# R7KA8T2AD register map
Vendor: Renesas Electronics Corporation; Series: RA8; File version: 1.10.02
CPU: CM85 r0p2, little endian, MPU, FPU, VTOR, 4 interrupt priority bits, 96 interrupts
Registers are 32-bit, read-write, reset 0x0 unless marked. A register's access mark holds for its fields unless they carry their own. Offsets are from the block's base; [hi:lo] are bit positions; {n}, {i} and the like mark numbered series; 'fields as' and 'values as' point back to an identical list; <NAME> marks a mode.

## SYSC — System Control
Base 0x4001E000
0x0C SBYCR 8-bit reset 0x40 — Standby Control Register
  [6] OPE — Output Port Enable
    0=In Software Standby mode or Deep Software Standby mode, Set the address bus and other bus control signal to the high-impedance state; 1=In Software Standby mode or Deep Software Standby mode, Address bus and other bus control signal retain the output state
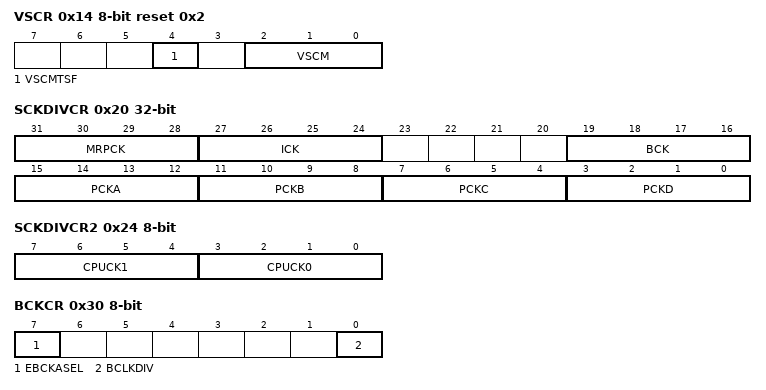
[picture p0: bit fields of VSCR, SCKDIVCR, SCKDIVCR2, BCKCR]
0x14 VSCR 8-bit reset 0x2 — Voltage Scaling Control Register
  [4] VSCMTSF ro — Voltage Scaling Control Mode Transition Status Flag
    0=Transition completed; 1=During transition
  [2:0] VSCM — Voltage Scaling Control Mode Bit
    1=VSCR_1; 2=VSCR_2 (default)
0x20 SCKDIVCR — System Clock Division Control Register
  [31:28] MRPCK — MRAM Clock (MRPCLK) Select
    0=x 1/1; 1=x 1/2; 2=x 1/4; 3=x 1/8; 4=x 1/16; 5=x 1/32; 6=x 1/64; 8=x 1/3; 9=x 1/6; 10=x 1/12; 11=x 1/24; other=Others (Setting prohibited.)
  [27:24] ICK — System Clock (ICLK) Select
    values as MRPCK
  [19:16] BCK — External Bus Clock (BCLK) Select
    0=x 1/1; 1=x 1/2; 2=x 1/4; 3=x 1/8; 4=x 1/16; 5=x 1/32; 6=x 1/64; 8=x 1/3; 9=x 1/6; 10=x 1/12; 11=x 1/24; other=Others (Settings prohibited)
  [15:12] PCKA — Peripheral Module Clock A (PCLKA) Select
    values as MRPCK
  [11:8] PCKB — Peripheral Module Clock B (PCLKB) Select
    values as MRPCK
  [7:4] PCKC — Peripheral Module Clock C (PCLKC) Select
    values as MRPCK
  [3:0] PCKD — Peripheral Module Clock D (PCLKD) Select
    values as MRPCK
0x24 SCKDIVCR2 8-bit — System Clock Division Control Register 2
  [7:4] CPUCK1 — CPU1 Clock (CPUCLK1) Select
    values as SCKDIVCR.MRPCK
  [3:0] CPUCK0 — CPU0 Clock (CPUCLK0) Select
    values as SCKDIVCR.MRPCK
0x26 SCKSCR 8-bit reset 0x1 — System Clock Source Control Register
  [2:0] CKSEL — Clock Source Select
    0=HOCO; 1=MOCO (Value after reset); 2=Setting prohibited; 3=Main clock oscillator (MOSC); 4=Sub-clock oscillator (SOSC); 5=PLL1 output clock P (PLL1P); 6=Setting prohibited; 7=Setting prohibited
0x2A PLLCR 8-bit reset 0x1 — PLL Control Register
  [0] PLLSTP — PLL1 Stop Control
    0=PLL1 is operating; 1=PLL1 is stopped
0x30 BCKCR 8-bit — External Bus Clock Control Register
  [7] EBCKASEL — External Bus Asynchronous Select
    0=Synchronous (BCLK); 1=Asynchronous (BCLKA)
  [0] BCLKDIV — BCLK Pin Output Select
    0=BCLK or BCLKA; 1=BCLK/2 or BCLKA/2
0x32 MOSCCR 8-bit reset 0x1 — Main Clock Oscillator Control Register
  [0] MOSTP — Main Clock Oscillator Stop
    0=Operate the main clock oscillator; 1=Stop the main clock oscillator
0x36 HOCOCR 8-bit (reset mask 0xFE) — High-Speed On-Chip Oscillator Control Register
  [0] HCSTP — HOCO Stop
    0=Operate the HOCO clock; 1=Stop the HOCO clock
0x37 HOCOCR2 8-bit (reset mask 0xF8) — High-Speed On-Chip Oscillator Control Register2
  [2:0] HCFRQ0 — HOCO Frequency Setting 0
    0=16 MHz; 1=18 MHz; 2=20 MHz; 4=32 MHz; 7=48 MHz
0x38 MOCOCR 8-bit — Middle-Speed On-Chip Oscillator Control Register
  [0] MCSTP — MOCO Stop
    0=MOCO clock is operating; 1=MOCO clock is stopped
0x39 FLLCR1 8-bit — FLL Control Register1
  [0] FLLEN — FLL Enable
    0=FLL function is disabled; 1=FLL function is enabled
0x3A FLLCR2 16-bit — FLL Control Register2
  [10:0] FLLCNTL — FLL Multiplication Control
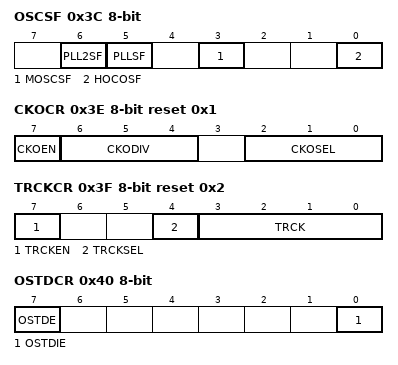
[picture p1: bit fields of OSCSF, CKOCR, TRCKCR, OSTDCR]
0x3C OSCSF 8-bit ro (reset mask 0xFE) — Oscillation Stabilization Flag Register
  [6] PLL2SF — PLL2 Clock Oscillation Stabilization Flag
    0=The PLL2 clock is stopped or is not yet stable; 1=The PLL2 clock is stable
  [5] PLLSF — PLL1 Clock Oscillation Stabilization Flag
    0=The PLL1 clock is stopped or is not yet stable; 1=The PLL1 clock is stable, so is available for use as the system clock source
  [3] MOSCSF — Main Clock Oscillation Stabilization Flag
    0=The main clock oscillator is stopped or is not yet stable; 1=The main clock oscillator is stable, so is available for use as the system clock source
  [0] HOCOSF — HOCO Clock Oscillation Stabilization Flag
    0=The HOCO clock is stopped or is not yet stable; 1=The HOCO clock is stable, so is available for use as the system clock source
0x3E CKOCR 8-bit reset 0x1 — Clock Out Control Register
  [7] CKOEN — Clock Out Enable
    0=Disable clock out; 1=Enable clock out
  [6:4] CKODIV — Clock Output Frequency Division Ratio
    0=x 1/1; 1=x 1/2; 2=x 1/4; 3=x 1/8; 4=x 1/16; 5=x 1/32; 6=x 1/64; 7=x 1/128
  [2:0] CKOSEL — Clock Out Source Select
    0=HOCO; 1=MOCO (Value after reset); 2=LOCO; 3=MOSC; 4=SOSC; other=Others (Setting prohibited)
0x3F TRCKCR 8-bit reset 0x2 — Trace Clock Control Register
  [7] TRCKEN — Trace Clock Operating Enable
    0=Stop; 1=Operation enable
  [4] TRCKSEL — Trace Clock Source Select
    0=System clock source (value after reset); 1=HOCO (oscillation in debug mode)
  [3:0] TRCK — Trace Clock Operating Frequency Select
    0=1/1; 1=1/2; 2=1/4 (value after reset); 3=1/8; 4=1/16; 5=1/32; 6=1/64; 7=1/128; 8=1/256; 9=1/3; 10=1/6; 11=1/12; other=Others (Setting prohibited)
0x40 OSTDCR 8-bit — Oscillation Stop Detection Control Register
  [7] OSTDE — Oscillation Stop Detection Function Enable
    0=Disable oscillation stop detection function; 1=Enable oscillation stop detection function
  [0] OSTDIE — Oscillation Stop Detection Interrupt Enable
    0=Disable oscillation stop detection interrupt (do not notify the POEG); 1=Enable oscillation stop detection interrupt (notify the POEG)
0x41 OSTDSR 8-bit — Oscillation Stop Detection Status Register
  [0] OSTDF — Oscillation Stop Detection Flag
    0=Main clock oscillation stop not detected; 1=Main clock oscillation stop detected
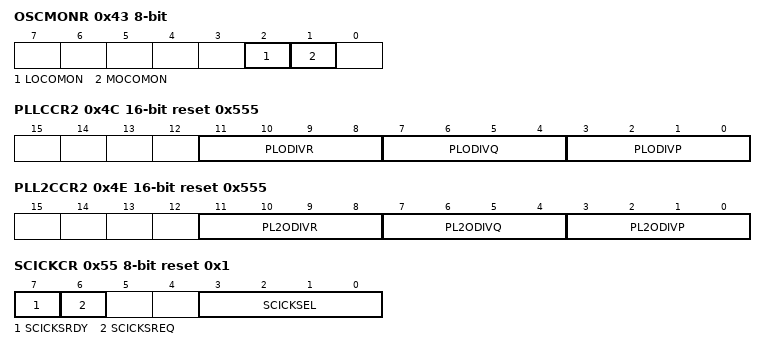
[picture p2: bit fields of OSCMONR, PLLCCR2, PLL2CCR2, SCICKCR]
0x43 OSCMONR 8-bit — Oscillator Monitor Register
  [2] LOCOMON ro — LOCO operation monitor
    0=LOCO is set to operate; 1=LOCO is set to stop
  [1] MOCOMON ro — MOCO operation monitor
    0=MOCO is set to operate; 1=MOCO is set to stop
0x4A PLL2CR 8-bit reset 0x1 — PLL2 Control Register
  [0] PLL2STP — PLL2 Stop Control
    0=PLL2 is operating; 1=PLL2 is stopped
0x4C PLLCCR2 16-bit reset 0x555 — PLL Clock Control Register 2
  [11:8] PLODIVR — PLL1 Output Frequency Division Ratio Select for output clock R
    {v}=× 1/{v+1} (v=1..4); 5=× 1/6 (Value after reset); 7=× 1/8; 8=× 1/9; 9=× 1/1.5; other=Others (Setting prohibited.)
  [7:4] PLODIVQ — PLL1 Output Frequency Division Ratio Select for output clock Q
    values as PLODIVR
  [3:0] PLODIVP — PLL1 Output Frequency Division Ratio Select for output clock P
    1=× 1/2; 2=× 1/3; 3=× 1/4; 5=× 1/6 (Value after reset); 7=× 1/8; 15=× 1/16; other=Others (Setting prohibited.)
0x4E PLL2CCR2 16-bit reset 0x555 — PLL2 Clock Control Register 2
  [11:8] PL2ODIVR — PLL2 Output Frequency Division Ratio Select for output clock R
    values as PLLCCR2.PLODIVR
  [7:4] PL2ODIVQ — PLL2 Output Frequency Division Ratio Select for output clock Q
    values as PLLCCR2.PLODIVR
  [3:0] PL2ODIVP — PLL2 Output Frequency Division Ratio Select for output clock P
    values as PLLCCR2.PLODIVP
0x52 EBCKOCR 8-bit — External Bus Clock Output Control Register
  [0] EBCKOEN — EBCLK Pin Output Control
    0=EBCLK pin output is disabled (fixed high); 1=EBCLK pin output is enabled
0x53 SDCKOCR 8-bit — SDRAM Clock Output Control Register
  [0] SDCKOEN — SDCLK Pin Output Control
    0=SDCLK pin output is disabled. (Fixed high); 1=SDCLK pin output is enabled
0x54 SCICKDIVCR 8-bit — SCI Clock Division Control Register
  [3:0] SCICKDIV — SCI clock (SCICLK) Division Select
    0=1/1 (Value after reset); 1=1/2; 2=1/4; 3=1/6; 4=1/8; 5=1/3; 6=1/5; 7=1/10; 8=1/16; 9=1/32; other=Others (Setting prohibited.)
0x55 SCICKCR 8-bit reset 0x1 — SCI Clock Control Register
  [7] SCICKSRDY ro — SCI Clock (SCICLK) Switching Ready state flag
    0=Impossible to switch; 1=Possible to switch
  [6] SCICKSREQ — SCI Clock (SCICLK) Switching Request
    0=No request; 1=Request switching
  [3:0] SCICKSEL — SCI Clock (SCICLK) Source Select
    0=HOCO; 1=MOCO (value after reset); 2=LOCO; 3=Main clock oscillator; 4=Sub-clock oscillator; 5=PLL1P; 6=PLL2P; 7=PLL1Q; 8=PLL1R; 9=PLL2Q; 10=PLL2R; other=Others (Setting prohibited)
0x56 SPICKDIVCR 8-bit — SPI Clock Division Control Register
  [3:0] SPICKDIV — SPI clock (SPICLK) Division Select
    values as SCICKDIVCR.SCICKDIV
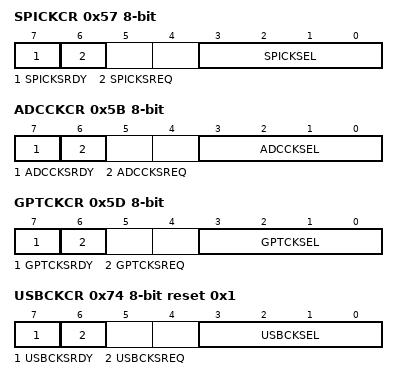
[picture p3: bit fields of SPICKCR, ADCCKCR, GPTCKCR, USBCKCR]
0x57 SPICKCR 8-bit — SPI Clock Control Register
  [7] SPICKSRDY ro — SPI clock (SPICLK) Switching Ready State Flag
    0=Impossible to switch; 1=Possible to switch
  [6] SPICKSREQ — SPI Clock (SPICLK) Switching Request
    0=No request; 1=Request switching
  [3:0] SPICKSEL — SPI Clock (SPICLK) Source Select
    values as SCICKCR.SCICKSEL
0x5A ADCCKDIVCR 8-bit — ADC Clock Division Control Register
  [3:0] ADCCKDIV — ADC Clock (ADCCLK) Division Select
    0=1/1 (value after reset); 1=1/2; 2=1/4; 3=1/6; 4=1/8; 7=1/10; 8=1/16; 9=1/32; other=Others (Setting prohibited)
0x5B ADCCKCR 8-bit — ADC Clock Control Register
  [7] ADCCKSRDY ro — ADC Clock (ADCCLK) Switching Ready State Flag
    0=Impossible to switch; 1=Possible to switch
  [6] ADCCKSREQ — ADC Clock (ADCCLK) Switching Request
    0=No request; 1=Request switching
  [3:0] ADCCKSEL — ADC Clock (ADCCLK) Source Select
    values as SCICKCR.SCICKSEL
0x5C GPTCKDIVCR 8-bit — GPT Clock Division Control Register
  [3:0] GPTCKDIV — GPT Clock (GPTCLK) Division Select
    0=1/1 (value after reset); 1=1/2; 2=1/4; 3=1/6; 4=1/8; 5=1/3; 6=1/5; 7=1/10; 8=1/16; 9=1/32; other=Others (Setting prohibited)
0x5D GPTCKCR 8-bit — GPT Clock Control Register
  [7] GPTCKSRDY — GPT Clock (GPTCLK) Switching Ready State Flag
    0=Impossible to switch; 1=Possible to switch
  [6] GPTCKSREQ — GPT Clock (GPTCLK) Switching Request
    0=No request; 1=Request switching
  [3:0] GPTCKSEL — GPT Clock (GPTCLK) Source Select
    0=HOCO; 1=MOCO (value after reset); 3=Main clock oscillator; 5=PLL1P; 6=PLL2P; 7=PLL1Q; 8=PLL1R; 9=PLL2Q; 10=PLL2R; other=Others (Setting prohibited.)
0x61 MOCOUTCR 8-bit — MOCO User Trimming Control Register
  [7:0] MOCOUTRM — MOCO User Trimming
0x62 HOCOUTCR 8-bit — HOCO User Trimming Control Register
  [7:0] HOCOUTRM — HOCO User Trimming
0x6C USBCKDIVCR 8-bit — USB Clock Division Control Register
  [3:0] USBCKDIV — USB Clock (USBCLK) Division Select
    0=1/1 (value after reset); 1=1/2; 2=1/4; 3=1/6; 4=1/8; 5=1/3; 6=1/5; 7=1/10; 8=1/16; 9=1/32; other=Others (Setting prohibited.)
0x6D OCTACKDIVCR 8-bit — Octal-SPI Clock Division Control Register
  [3:0] OCTACKDIV — Octal-SPI Clock (OCTACLK) Division Select
    values as SCICKDIVCR.SCICKDIV
0x6E CANFDCKDIVCR 8-bit — CANFD Core Clock Division Control Register
  [3:0] CANFDCKDIV — CANFD core clock (CANFDCLK) Division Select
    0=1/1 (Value after reset); 1=1/2; 2=1/4; 3=1/6; 4=1/8; 5=1/3; 6=1/5; 7=1/10; 8=1/16; 9=1/32; other=Others (Setting prohibited)
0x70 I3CCKDIVCR 8-bit — I3C Clock Division Control Register
  [3:0] I3CCKDIV — I3C clock (I3CCLK) Division Select
    values as SCICKDIVCR.SCICKDIV
0x74 USBCKCR 8-bit reset 0x1 — USB Clock Control Register
  [7] USBCKSRDY ro — USB Clock (USBCLK) Switching Ready state flag
    0=Impossible to Switch; 1=Possible to Switch
  [6] USBCKSREQ — USB Clock (USBCLK) Switching Request
    0=No request; 1=Request switching
  [3:0] USBCKSEL — USB Clock (USBCLK) Source Select
    0=HOCO; 1=MOCO (Value after reset); 3=Main clock oscillator; 5=PLL1P; 6=PLL2P; 7=PLL1Q; 8=PLL1R; 9=PLL2Q; 10=PLL2R; other=Others (Setting prohibited.)
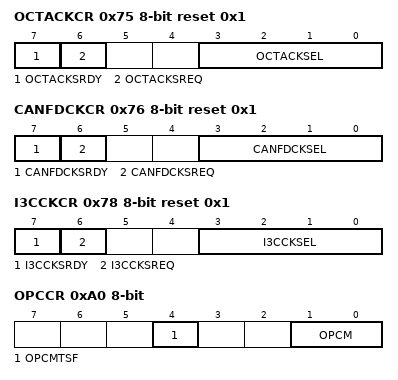
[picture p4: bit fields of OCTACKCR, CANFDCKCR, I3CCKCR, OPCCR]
0x75 OCTACKCR 8-bit reset 0x1 — Octal-SPI Clock Control Register
  [7] OCTACKSRDY ro — Octal-SPI Clock (OCTACLK) Switching Ready state flag
    0=Impossible to Switch; 1=Possible to Switch
  [6] OCTACKSREQ — Octal-SPI Clock (OCTACLK) Switching Request
    0=No request; 1=Request switching
  [3:0] OCTACKSEL — Octal-SPI Clock (OCTACLK) Source Select
    0=HOCO; 1=MOCO (Value after reset); 2=LOCO; 3=Main clock oscillator; 4=Sub-clock oscillator; 5=PLL1P; 6=PLL2P; 7=PLL1Q; 8=PLL1R; 9=PLL2Q; 10=PLL2R; other=Others (Setting prohibited.)
0x76 CANFDCKCR 8-bit reset 0x1 — CANFD Core Clock Control Register
  [7] CANFDCKSRDY ro — CANFD Core Clock (CANFDCLK) Switching Ready state flag
    0=Impossible to Switch; 1=Possible to Switch
  [6] CANFDCKSREQ — CANFD Core Clock (CANFDCLK) Switching Request
    0=No request; 1=Request switching
  [3:0] CANFDCKSEL — CANFD Core Clock (CANFDCLK) Source Select
    values as OCTACKCR.OCTACKSEL
0x78 I3CCKCR 8-bit reset 0x1 — I3C Clock Control Register
  [7] I3CCKSRDY ro — I3C Clock (I3CCLK) Switching Ready state flag
    0=Impossible to switch; 1=Possible to switch
  [6] I3CCKSREQ — I3C Clock (I3CCLK) Switching Request
    0=No request; 1=Request switching
  [3:0] I3CCKSEL — I3C Clock (I3CCLK) Source Select
    1=MOCO (value after reset); 5=PLL1P; 6=PLL2P; 7=PLL1Q; 8=PLL1R; 9=PLL2Q; 10=PLL2R
0x7C MOSCSCR 8-bit — Main Clock Oscillator Standby Control Register
  [0] MOSCSOKP — Main Clock Oscillator Standby Oscillation Keep select
    0=Disable; 1=Enable
0x7D HOCOSCR 8-bit — High-Speed On-Chip Oscillator Standby Control Register
  [0] HOCOSOKP — HOCO Standby Oscillation Keep select.
    0=Disable; 1=Enable
0x84 MOCOSCR 8-bit — Middle-Speed On-Chip Oscillator Standby Control Register
  [0] MOCOSOKP — MOCO Standby Oscillation Keep select
    0=Disable; 1=Enable
0xA0 OPCCR 8-bit — Operating Power Control Register
  [4] OPCMTSF ro — Operating Power Control Mode Transition Status Flag
    0=Transition completed; 1=During transition
  [1:0] OPCM — Operating Power Control Mode Select
    0=High-speed mode; 1=Prohibited; 2=Prohibited; 3=Prohibited
0xA2 MOSCWTCR 8-bit reset 0x5 — Main Clock Oscillator Wait Control Register
  [3:0] MSTS — Main Clock Oscillator Wait Time Setting
    0=Wait time = 3 cycles (11.4 us); 1=Wait time = 35 cycles (133.5 us); 2=Wait time = 67 cycles (255.6 us); 3=Wait time = 131 cycles (499.7 us); 4=Wait time = 259 cycles (988.0 us); 5=Wait time = 547 cycles (2086.6 us); 6=Wait time = 1059 cycles (4039.8 us); 7=Wait time = 2147 cycles (8190.2 us); 8=Wait time = 4291 cycles (16368.9 us); 9=Wait time = 8163 cycles (31139.4 us); other=Others (Setting prohibited)
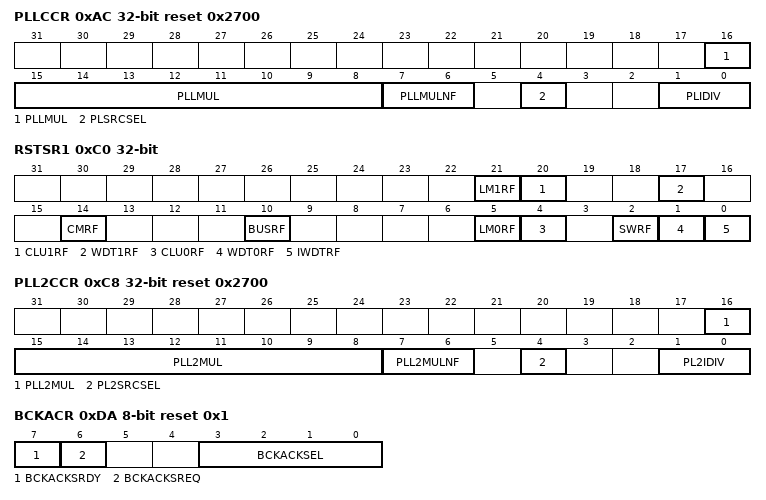
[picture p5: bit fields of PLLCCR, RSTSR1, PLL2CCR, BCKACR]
0xAC PLLCCR reset 0x2700 — PLL Clock Control Register
  [16:8] PLLMUL range 0x13..0x3B — PLL1 Frequency Multiplication Factor Select
  [7:6] PLLMULNF — PLL1 Frequency Multiplication Fractional Factor Select
    0=0.00 (Value after reset); 1=0.33 (1/3); 2=0.66 (2/3); 3=0.50 (1/2)
  [4] PLSRCSEL — PLL1 Clock Source Select
    0=Main clock oscillator; 1=HOCO
  [1:0] PLIDIV — PLL1 Input Frequency Division Ratio Select
    0=1/1; 1=1/2; 2=1/3; other=Others (Setting prohibited.)
0xC0 RSTSR1 (reset mask 0xFFCDBBC8) — Reset Status Register 1
  [21] LM1RF — Local memory 1 error Reset Detect Flag
    0=Local memory 1 error reset not detected; 1=Local memory 1 error reset detected
  [20] CLU1RF — CPU1 Lockup Reset Detect Flag
    0=CPU1 lockup reset not detected; 1=CPU1 lockup reset detected
  [17] WDT1RF — Watchdog Timer 1 Reset Detect Flag
    0=Watchdog timer 1 reset not detected; 1=Watchdog timer 1 reset detected
  [14] CMRF — Common Memory Error Reset Detect Flag
    0=Common memory error reset not detected; 1=Common memory error reset detected
  [10] BUSRF — Bus Error Reset Detect Flag
    0=Bus error reset not detected; 1=Bus error reset detected
  [5] LM0RF — Local memory 0 error Reset Detect Flag
    0=Local memory 0 error reset not detected; 1=Local memory 0 error reset detected
  [4] CLU0RF — CPU0 Lockup Reset Detect Flag
    0=CPU0 lockup reset not detected; 1=CPU0 lockup reset detected
  [2] SWRF — Software Reset Detect Flag
    0=Software reset not detected; 1=Software reset detected
  [1] WDT0RF — Watchdog Timer 0 Reset Detect Flag
    0=Watchdog timer 0 reset not detected; 1=Watchdog timer 0 reset detected
  [0] IWDTRF — Independent Watchdog Timer Reset Detect Flag
    0=Independent watchdog timer reset not detected; 1=Independent watchdog timer reset detected
0xC8 PLL2CCR reset 0x2700 — PLL2 Clock Control Register
  [16:8] PLL2MUL — PLL2 Frequency Multiplication Factor Select
  [7:6] PLL2MULNF — PLL2 Frequency Multiplication Fractional Factor Select
    values as PLLCCR.PLLMULNF
  [4] PL2SRCSEL — PLL2 Clock Source Select
    0=Main clock oscillator; 1=HOCO
  [1:0] PL2IDIV — PLL2 Input Frequency Division Ratio Select
    0=1/1 (Value after reset); 1=1/2; 2=1/3; other=Others (Setting prohibited.)
0xCC SYRACCR 8-bit ro — System Register Access Control Register
  [0] BUSY — Access Ready monitor
    0=Ready to read/write access; 1=Writing in progress
0xD4 BCKADIVCR 8-bit — Asynchronous External Bus Clock Division Control Register
  [3:0] BCKACKDIV — Asynchronous External Bus Clock (BCLKA) Division Select
    values as ADCCKDIVCR.ADCCKDIV
0xD5 ESWCKDIVCR 8-bit — EtherSW Clock Division Control Register
  [3:0] ESWCKDIV — EtherSW Clock (ESWCLK) Division Select
    values as ADCCKDIVCR.ADCCKDIV
0xD6 ESWPCKDIVCR 8-bit — EtherSW-PHY Clock Division Control Register
  [3:0] ESWPCKDIV — EtherSW-PHY Clock (ESWPHYCLK) Division Select
    values as ADCCKDIVCR.ADCCKDIV
0xD7 ESCCKDIVCR 8-bit — EtherCAT Clock Division Control Register
  [3:0] ESCCKDIV — EtherCAT Clock (ESCCLK) Division Select
    values as GPTCKDIVCR.GPTCKDIV
0xD8 ETHPCKDIVCR 8-bit — Ether-PHY Clock Division Control Register
  [3:0] ETHPCKDIV — Ether-PHY Clock (ETHPHYCLK) Division Select
    values as ADCCKDIVCR.ADCCKDIV
0xD9 DSMIFCKDIVCR 8-bit — DSMIF Clock Division Control Register
  [3:0] DSMIFCKDIV — DSMIF Clock (DSMIFCLK) Division Select
    values as GPTCKDIVCR.GPTCKDIV
0xDA BCKACR 8-bit reset 0x1 — Asynchronous External Bus Clock Control Register
  [7] BCKACKSRDY ro — Asynchronous External Bus Clock (BCLKA) Switching Ready State Flag
    0=Impossible to switch; 1=Possible to switch
  [6] BCKACKSREQ — Asynchronous External Bus Clock (BCLKA) Switching Request
    0=No request; 1=Request switching
  [3:0] BCKACKSEL — Asynchronous External Bus Clock (BCLKA)
    1=MOCO (value after reset); 5=PLL1P; 6=PLL2P; 7=PLL1Q; 8=PLL1R; 9=PLL2Q; 10=PLL2R; other=Others (Setting prohibited.)
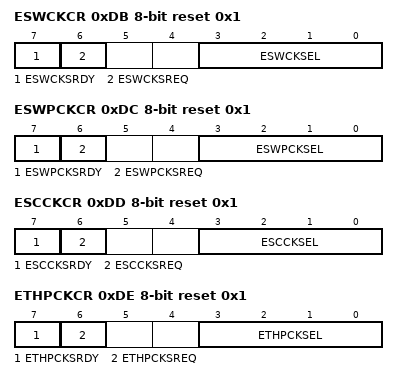
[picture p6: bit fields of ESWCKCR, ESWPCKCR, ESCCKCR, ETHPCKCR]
0xDB ESWCKCR 8-bit reset 0x1 — EtherSW Clock Control Register
  [7] ESWCKSRDY ro — EtherSW Clock (ESWCLK) Switching Ready State Flag
    0=Impossible to switch; 1=Possible to switch
  [6] ESWCKSREQ — EtherSW Clock (ESWCLK) Switching Request
    0=No request; 1=Request switching
  [3:0] ESWCKSEL — EtherSW Clock (ESWCLK) Source Select
    1=MOCO (value after reset); 5=PLL1P; 6=PLL2P; 7=PLL1Q; 8=PLL1R; 9=PLL2Q; 10=PLL2R; other=Others (Setting prohibited)
0xDC ESWPCKCR 8-bit reset 0x1 — EtherSW-PHY Clock Control Register
  [7] ESWPCKSRDY ro — EtherSW-PHY Clock (ESWPHYCLK) Switching Ready State Flag
    0=Impossible to switch; 1=Possible to switch
  [6] ESWPCKSREQ — EtherSW-PHY Clock (ESWPHYCLK) Switching Request
    0=No request; 1=Request switching
  [3:0] ESWPCKSEL — EtherSW-PHY Clock (ESWPHYCLK) Source Select
    values as ESWCKCR.ESWCKSEL
0xDD ESCCKCR 8-bit reset 0x1 — EtherCAT Clock Control Register
  [7] ESCCKSRDY ro — EtherCAT Clock (ESCCLK) Switching Ready State Flag
    0=Impossible to switch; 1=Possible to switch
  [6] ESCCKSREQ — EtherCAT Clock (ESCCLK) Switching Request
    0=No request; 1=Request switching
  [3:0] ESCCKSEL — EtherCAT Clock (ESCCLK) Source Select
    values as BCKACR.BCKACKSEL
0xDE ETHPCKCR 8-bit reset 0x1 — Ether-PHY Clock Control Register
  [7] ETHPCKSRDY ro — Ether-PHY Clock (ETHPHYCLK) Switching Ready State Flag
    0=Impossible to switch; 1=Possible to switch
  [6] ETHPCKSREQ — Ether-PHY Clock (ETHPHYCLK) Switching Request
    0=No request; 1=Request switching
  [3:0] ETHPCKSEL — Ether-PHY Clock (ETHPHYCLK) Source Select
    1=MOCO (value after reset); 3=Main clock oscillator; 5=PLL1P; 6=PLL2P; 7=PLL1Q; 8=PLL1R; 9=PLL2Q; 10=PLL2R; other=Others (Setting prohibited)
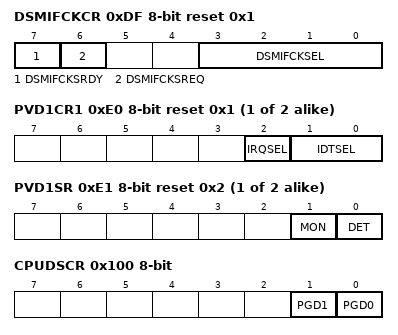
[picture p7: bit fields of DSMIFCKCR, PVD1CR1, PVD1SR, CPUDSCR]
0xDF DSMIFCKCR 8-bit reset 0x1 — DSMIF Clock Control Register
  [7] DSMIFCKSRDY ro — DSMIF Clock (DSMIFCLK) Switching Ready State Flag
    0=Impossible to switch; 1=Possible to switch
  [6] DSMIFCKSREQ — DSMIF Clock (DSMIFCLK) Switching Request
    0=No request; 1=Request switching
  [3:0] DSMIFCKSEL — DSMIF Clock (DSMIFCLK) Source Select
    values as BCKACR.BCKACKSEL
{0xDE+2i} PVD{i}CR1 (i=1..2) 8-bit reset 0x1 — Voltage Monitor {i} Circuit Control Register
  [2] IRQSEL — Voltage Monitor m Interrupt Type Select
    0=Non-maskable interrupt; 1=Maskable interrupt
  [1:0] IDTSEL — Voltage Monitor m Interrupt Generation Condition Select
{0xDF+2i} PVD{i}SR (i=1..2) 8-bit reset 0x2 — Voltage Monitor {i} Circuit Status Register
  [1] MON — Voltage Monitor 1 Signal Monitor Flag
  [0] DET — Voltage Monitor m Voltage Change Detection Flag
0x100 CPUDSCR 8-bit — CPU Deep Sleep Control Register
  [1] PGD1 — Power Gating Disable for CPU1
    0=Power Gating Enable during CPU1 Deep Sleep (default); 1=Power Gating Disable during CPU1 Deep Sleep
  [0] PGD0 — Power Gating Disable for CPU0
    0=Power Gating Enable during CPU0 Deep Sleep (default); 1=Power Gating Disable during CPU0 Deep Sleep
0x104 PGSCR 8-bit reset 0x1 — Power Gating Shift Control Register
  [0] PGS — Power gating shift timing
    0=Power gating control for each domain is started partial at the same time; 1=Power gating control for each domain is started serially
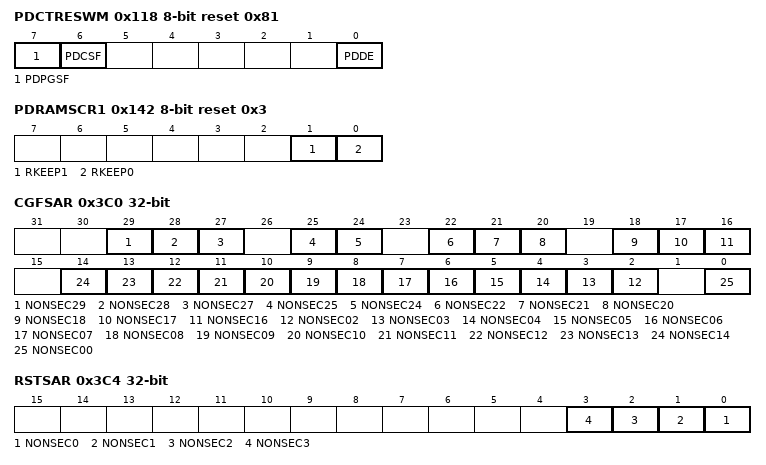
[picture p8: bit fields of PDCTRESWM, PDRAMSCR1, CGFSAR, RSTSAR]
0x118 PDCTRESWM 8-bit reset 0x81 — ESWM Power Domain Control Register
  [7] PDPGSF ro — Power gating status flag
    0=Target domain is power on (not gating); 1=Target domain is power off (during Gating)
  [6] PDCSF ro — Power control status flag
    0=Power gating control is not executed (idle); 1=Power gating control is in progress
  [0] PDDE — Power control enable
    0=Power on the target domain; 1=Power off the target domain
0x140 PDRAMSCR0 16-bit reset 0x7FFF — SRAM Power Domain Standby Control Register 0
  [12:0] RKEEP — RAM Retention
    0=When entering the Software Standby mode, the contents of the target RAM are not kept; 1=When entering the Software Standby mode, the contents of the target RAM are kept
0x142 PDRAMSCR1 8-bit reset 0x3 — SRAM Power Domain Standby Control Register 1
  [1] RKEEP1 — RAM Retention
    values as PDRAMSCR0.RKEEP
  [0] RKEEP0 — RAM Retention
    0=When entering the CPU0 Deep Sleep and Software Standby mode, the contents of the target RAM are not kept; 1=When entering the CPU0 Deep Sleep and Software Standby mode, the contents of the target RAM are kept
{0x210+2i} PSSTCR{i} (i=2..5) 16-bit — Power Switch Control Start Time Control Register {i}
  [12:0] PSST — Power switch control start time
0x3B0 VBRSABAR 16-bit reset 0xFFE0 — VBATT Backup Register Security Attribute Boundary Address Register
  [15:0] SABA — Boundary address between secure and non-secure
0x3B4 VBRPABARS 16-bit — VBATT Backup Register Privilege Attribute Boundary Address Register for Secure Region
  [15:0] PABAS — Privilege Attribute Boundary Address for Secure Region
0x3C0 CGFSAR — Clock Generation Function Security Attribute Register
  [all] fields
    0=Secure; 1=Non Secure
  [29] NONSEC29 — Non Secure Attribute bit 29
  [28] NONSEC28 — Non Secure Attribute bit 28
  [27] NONSEC27 — Non Secure Attribute bit 27
  [25] NONSEC25 — Non Secure Attribute bit 25
  [24] NONSEC24 — Non Secure Attribute bit 24
  [22] NONSEC22 — Non Secure Attribute bit 22
  [21] NONSEC21 — Non Secure Attribute bit 21
  [20] NONSEC20 — Non Secure Attribute bit 20
  [18] NONSEC18 — Non Secure Attribute bit 18
  [17] NONSEC17 — Non Secure Attribute bit 17
  [16] NONSEC16 — Non Secure Attribute bit 16
  [n] NONSEC{n:02} (n=2..14) — Non Secure Attribute bit {n:02}
  [0] NONSEC00 — Non Secure Attribute bit 00
0x3C4 RSTSAR — Reset Security Attribution Register
  [all] fields
    0=Secure; 1=Non-secure
  [n] NONSEC{n} (n=0..3) — Non-secure Attribute bit {n}
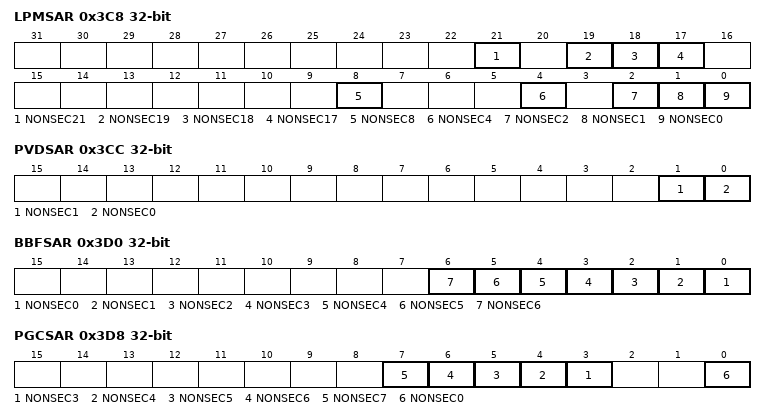
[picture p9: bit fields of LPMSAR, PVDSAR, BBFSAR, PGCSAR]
0x3C8 LPMSAR — Low Power Mode Security Attribution Register
  [all] fields
    0=Secure; 1=Non-secure
  [21] NONSEC21 — Non-secure Attribute bit 21
  [19] NONSEC19 — Non-secure Attribute bit 19
  [18] NONSEC18 — Non-secure Attribute bit 18
  [17] NONSEC17 — Non-secure Attribute bit 17
  [8] NONSEC8 — Non-secure Attribute bit 8
  [4] NONSEC4 — Non-secure Attribute bit 4
  [2] NONSEC2 — Non-secure Attribute bit 2
  [1] NONSEC1 — Non-secure Attribute bit 1
  [0] NONSEC0 — Non-secure Attribute bit 0
0x3CC PVDSAR — Programable Voltage Detection Security Attribution Register
  [1] NONSEC1 — Non Secure Attribute bit 1
    0=Secure; 1=Non Secure
  [0] NONSEC0 — Non Secure Attribute bit 0
    0=Secure; 1=Non Secure
0x3D0 BBFSAR — Battery Backup Function Security Attribute Register
  [all] fields
    0=Secure; 1=Non Secure
  [n] NONSEC{n} (n=0..6) — Non Secure Attribute bit {n}
0x3D8 PGCSAR — Power Gating Control Security Attribution Register
  [all] fields
    0=Secure; 1=Non-secure
  [n] NONSEC{n} (n=3..7) — Non-secure Attribute bit {n}
  [0] NONSEC0 — Non-secure Attribute bit 0
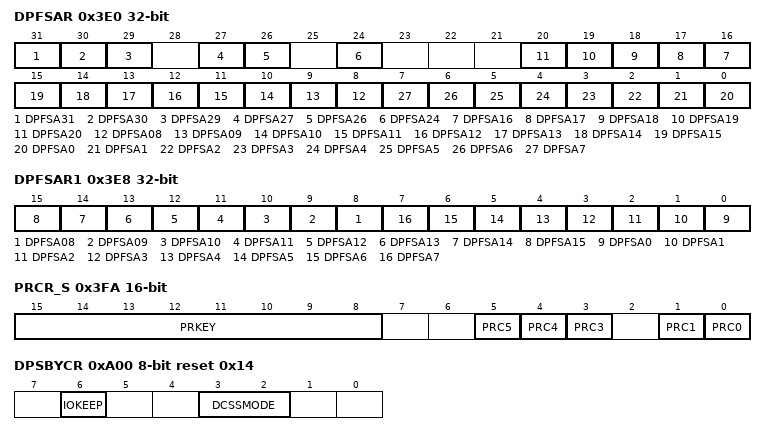
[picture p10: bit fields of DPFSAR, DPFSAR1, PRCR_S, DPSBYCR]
0x3E0 DPFSAR — Deep Software Standby Interrupt Factor Security Attribution Register
  [all] fields
    0=Secure; 1=Non-secure
  [31] DPFSA31 — Deep Software Standby Interrupt Factor Security Attribute bit 31
  [30] DPFSA30 — Deep Software Standby Interrupt Factor Security Attribute bit 30
  [29] DPFSA29 — Deep Software Standby Interrupt Factor Security Attribute bit 29
  [27] DPFSA27 — Deep Software Standby Interrupt Factor Security Attribute bit 27
  [26] DPFSA26 — Deep Software Standby Interrupt Factor Security Attribute bit 26
  [24] DPFSA24 — Deep Software Standby Interrupt Factor Security Attribute bit 24
  [n] DPFSA{n} (n=16..20) — Deep Software Standby Interrupt Factor Security Attribute bit {n}
  [n] DPFSA{n:02} (n=8..15) — Deep Software Standby Interrupt Factor Security Attribute bit n (n = 8 to 15)
  [n] DPFSA{n} (n=0..7) — Deep Software Standby Interrupt Factor Security Attribute bit n (n = 0 to 7)
0x3E4 RSCSAR — RAM Standby Control Security Attribution Register
  [17:0] RSCSA — RAM Standby Control Security Attribute bit n (n = 0 to 17)
    0=Secure; 1=Non-secure
0x3E8 DPFSAR1 — Deep Software Standby Interrupt Factor Security Attribution Register 1
  [all] fields
    0=Secure; 1=Non-secure
  [n] DPFSA{n:02} (n=8..15) — Deep Software Standby Interrupt Factor Security Attribute bit n (n = 8 to 15)
  [n] DPFSA{n} (n=0..7) — Deep Software Standby Interrupt Factor Security Attribute bit n (n = 0 to 7)
0x3FA PRCR_S 16-bit — Protect Register for Secure
  [15:8] PRKEY wo — PRC Key Code
  [5] PRC5
    0=Write disabled; 1=Write enabled
  [4] PRC4
    0=Write disabled; 1=Write enabled
  [3] PRC3 — Enable writing to the registers related to the PVD
    0=Write disabled; 1=Write enabled
  [1] PRC1 — Enable writing to the registers related to the low power modes, and the battery backup function
    0=Write disabled; 1=Write enabled
  [0] PRC0 — Enable writing to the registers related to the clock generation circuit
    0=Write disabled; 1=Write enabled
0x400 LOCOCR 8-bit — Low-Speed On-Chip Oscillator Control Register
  [0] LCSTP — LOCO Stop
    0=Operate the LOCO clock; 1=Stop the LOCO clock
0x402 LOCOUTCR 8-bit — LOCO User Trimming Control Register
  [7:0] LOCOUTRM — LOCO User Trimming
0xA00 DPSBYCR 8-bit reset 0x14 — Deep Software Standby Control Register
  [6] IOKEEP — I/O Port Retention
    0=When the Deep Software Standby mode is canceled, the I/O ports and D/A output are in the reset state; 1=When the Deep Software Standby mode is canceled, the I/O ports and D/A output are in the same state as in the Deep Software Standby mode
  [3:2] DCSSMODE — DCDC soft start mode
    0=Setting prohibited; 1=128 µs; 2=256 µs; 3=512 µs
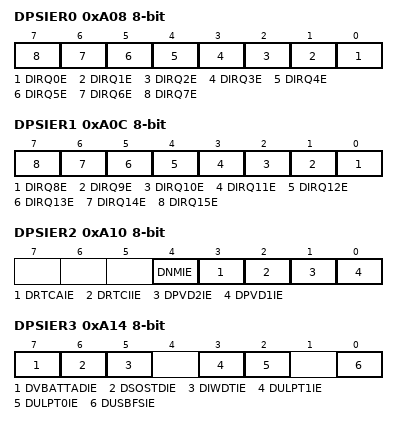
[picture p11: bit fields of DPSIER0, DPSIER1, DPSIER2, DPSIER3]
0xA08 DPSIER0 8-bit — Deep Software Standby Interrupt Enable Register 0
  [all] fields
    0=Cancelling Deep Software Standby mode is disabled; 1=Cancelling Deep Software Standby mode is enabled
  [n] DIRQ{n}E (n=0..7) — IRQ{n}-DS Pin Enable
0xA0C DPSIER1 8-bit — Deep Software Standby Interrupt Enable Register 1
  [all] fields
    0=Canceling Deep Software Standby mode is disabled; 1=Canceling Deep Software Standby mode is enabled
  [n-8] DIRQ{n}E (n=8..15) — IRQ{n}-DS Pin Enable
0xA10 DPSIER2 8-bit — Deep Software Standby Interrupt Enable Register 2
  [all] fields
    values as the fields of DPSIER1
  [4] DNMIE — NMI Pin Deep Software Standby Cancel Signal Enable
  [3] DRTCAIE — RTC Alarm interrupt Deep Software Standby Cancel Signal Enable
  [2] DRTCIIE — RTC Interval interrupt Deep Software Standby Cancel Signal Enable
  [1] DPVD2IE — PVD2 Deep Software Standby Cancel Signal Enable
  [0] DPVD1IE — PVD1 Deep Software Standby Cancel Signal Enable
0xA14 DPSIER3 8-bit — Deep Software Standby Interrupt Enable Register 3
  [all] fields
    values as the fields of DPSIER1
  [7] DVBATTADIE — VBATT Tamper Detection Deep Software Standby Cancel Signal Enable
  [6] DSOSTDIE — Sub-clock Oscillation stop detection Deep Software Standby Cancel Signal Enable
  [5] DIWDTIE — IWDT Overflow Deep Software Standby Cancel Signal Enable
  [3] DULPT1IE — ULPT1 Overflow Deep Software Standby Cancel Signal Enable
  [2] DULPT0IE — ULPT0 Overflow Deep Software Standby Cancel Signal Enable
  [0] DUSBFSIE — USBFS Suspend/Resume Deep Software Standby Cancel Signal Enable
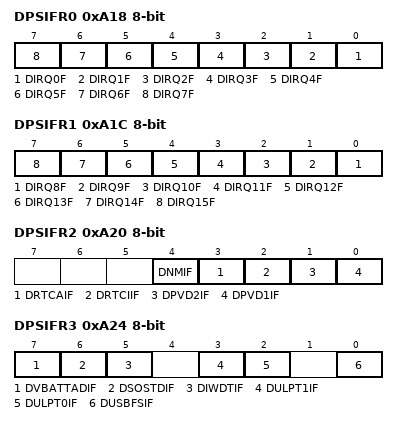
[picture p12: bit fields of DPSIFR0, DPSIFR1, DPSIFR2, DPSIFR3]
0xA18 DPSIFR0 8-bit — Deep Software Standby Interrupt Flag Register 0
  [all] fields
    0=The cancel request is not generated; 1=The cancel request is generated
  [n] DIRQ{n}F (n=0..7) — IRQ{n}-DS Pin Deep Software Standby Cancel Flag
0xA1C DPSIFR1 8-bit — Deep Software Standby Interrupt Flag Register 1
  [all] fields
    values as the fields of DPSIFR0
  [n-8] DIRQ{n}F (n=8..15) — IRQ{n}-DS Pin Deep Software Standby Cancel Flag
0xA20 DPSIFR2 8-bit — Deep Software Standby Interrupt Flag Register 2
  [all] fields
    values as the fields of DPSIFR0
  [4] DNMIF — NMI Pin Deep Software Standby Cancel Flag
  [3] DRTCAIF — RTC Alarm Interrupt Deep Software Standby Cancel Flag
  [2] DRTCIIF — RTC Interval Interrupt Deep Software Standby Cancel Flag
  [1] DPVD2IF — PVD2 Deep Software Standby Cancel Flag
  [0] DPVD1IF — PVD1 Deep Software Standby Cancel Flag
0xA24 DPSIFR3 8-bit — Deep Software Standby Interrupt Flag Register 3
  [all] fields
    values as the fields of DPSIFR0
  [7] DVBATTADIF — VBATT Tamper Detection Deep Software Standby Cancel Flag
  [6] DSOSTDIF — Sub-clock Oscillation stop detection Deep Software Standby Cancel Flag
  [5] DIWDTIF — IWDT Overflow Deep Software Standby Cancel Flag
  [3] DULPT1IF — ULPT1 Overflow Deep Software Standby Cancel Flag
  [2] DULPT0IF — ULPT0 Overflow Deep Software Standby Cancel Flag
  [0] DUSBFSIF — USBFS Suspend/Resume Deep Software Standby Cancel Flag
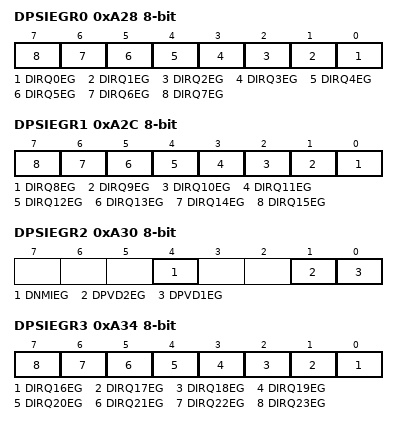
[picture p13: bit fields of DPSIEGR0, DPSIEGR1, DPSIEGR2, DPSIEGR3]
0xA28 DPSIEGR0 8-bit — Deep Software Standby Interrupt Edge Register 0
  [all] fields
    0=A cancel request is generated at a falling edge; 1=A cancel request is generated at a rising edge
  [n] DIRQ{n}EG (n=0..7) — IRQ{n}-DS Pin Edge Select
0xA2C DPSIEGR1 8-bit — Deep Software Standby Interrupt Edge Register 1
  [all] fields
    values as the fields of DPSIEGR0
  [n-8] DIRQ{n}EG (n=8..15) — IRQ{n}-DS Pin Edge Select
0xA30 DPSIEGR2 8-bit — Deep Software Standby Interrupt Edge Register 2
  [4] DNMIEG — NMI Pin Edge Select
    values as the fields of DPSIEGR0
  [1] DPVD2EG — PVD2 Edge Select
    0=A cancel request is generated when VCC < Vdet2 (fall) is detected; 1=A cancel request is generated when VCC ≥ Vdet2 (rise) is detected
  [0] DPVD1EG — PVD1 Edge Select
    0=A cancel request is generated when VCC < Vdet1 (fall) is detected; 1=A cancel request is generated when VCC ≥ Vdet1 (rise) is detected
0xA34 DPSIEGR3 8-bit — Deep Software Standby Interrupt Edge Register 3
  [all] fields
    values as the fields of DPSIEGR0
  [n-16] DIRQ{n}EG (n=16..23) — IRQ{n}-DS Pin Edge Select
0xA38 SYOCDCR 8-bit reset 0x80 — System Control OCD Control Register
  [7] DBGEN — Debugger Enable bit
    0=Disable on-chip debugger function; 1=Enable on-chip debugger function
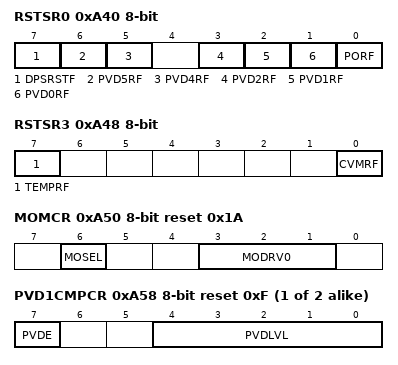
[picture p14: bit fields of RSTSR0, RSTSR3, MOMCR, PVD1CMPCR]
0xA40 RSTSR0 8-bit (reset mask 0x10) — Reset Status Register 0
  [7] DPSRSTF — Deep Software Standby Reset Flag
    0=Deep Software Standby Mode cancellation not requested by an interrupt or a reset; 1=Deep Software Standby Mode cancellation requested by an interrupt or a reset
  [6] PVD5RF — Voltage Monitor 5 Reset Detect Flag
    0=Voltage monitor 5 reset not detected; 1=Voltage monitor 5 reset detected
  [5] PVD4RF — Voltage Monitor 4 Reset Detect Flag
    0=Voltage monitor 4 reset not detected; 1=Voltage monitor 4 reset detected
  [3] PVD2RF — Voltage Monitor 2 Reset Detect Flag
    0=Voltage monitor 2 reset not detected; 1=Voltage monitor 2 reset detected
  [2] PVD1RF — Voltage Monitor 1 Reset Detect Flag
    0=Voltage monitor 1 reset not detected; 1=Voltage monitor 1 reset detected
  [1] PVD0RF — Voltage Monitor 0 Reset Detect Flag
    0=Voltage monitor 0 reset not detected; 1=Voltage monitor 0 reset detected
  [0] PORF — Power-On Reset Detect Flag
    0=Power-on reset not detected; 1=Power-on reset detected
0xA44 RSTSR2 8-bit (reset mask 0xFE) — Reset Status Register 2
  [0] CWSF — Cold/Warm Start Determination Flag
    0=Cold start; 1=Warm start
0xA48 RSTSR3 8-bit (reset mask 0x7E) — Reset Status Register 3
  [7] TEMPRF — Temperature Monitor Reset Detect Flag
    0=Temperature monitor reset not detected; 1=Temperature monitor reset detected
  [0] CVMRF — Core Voltage Monitor Reset Detect Flag
    0=Core voltage monitor reset not detected; 1=Core voltage monitor reset detected
0xA50 MOMCR 8-bit reset 0x1A — Main Clock Oscillator Mode Oscillation Control Register
  [6] MOSEL — Main Clock Oscillator Switching
    0=Resonator; 1=External clock input
  [3:1] MODRV0 — Main Clock Oscillator Drive Capability 0 Switching
    0=8 MHz; 3=8MHz to 24MHz; 5=8MHz to 48MHz; other=Others (Setting prohibited)
0xA54 FWEPROR 8-bit reset 0x2 — Flash P/E Protect Register
  [1:0] FLWE — Flash Programming and Erasure
    0=Prohibits Program, Block Erase, Multi Block Erase, Blank Check, and Configuration set command processing; 1=Permits Program, Block Erase, Multi Block Erase, Blank Check, and Configuration set command processing; 2=Prohibits Program, Block Erase, Multi Block Erase, Blank Check, and Configuration set command processing; 3=Prohibits Program, Block Erase, Multi Block Erase, Blank Check, and Configuration set command processing
{0xA54+4i} PVD{i}CMPCR (i=1..2) 8-bit reset 0xF — Voltage Monitor {i} Comparator Control Register
  [7] PVDE — Voltage Detection m Enable
    0=Voltage detection m circuit disabled; 1=Voltage detection m circuit enabled
  [4:0] PVDLVL — Detection Voltage m Level Select
    3=3.86 V (Vdetm_3); 4=3.14 V (Vdetm_4); 5=3.10 V (Vdetm_5); 6=3.08 V (Vdetm_6); 7=2.85 V (Vdetm_7); 8=2.83 V (Vdetm_8); 9=2.80 V (Vdetm_9); 10=2.62V (Vdetm_10); 11=2.33V (Vdetm_11); 12=1.90V (Vdetm_12); 13=1.86V (Vdetm_13); 14=1.74V (Vdetm_14); 15=1.71V (Vdetm_15); other=Others (Setting prohibited)
{0xA54+4i} PVD{i}CMPCR (i=4..5) 8-bit reset 0xF — Voltage Monitor {i} Comparator Control Register
  [7] PVDE — Voltage Detection n Enable
    0=Voltage detection n circuit disabled; 1=Voltage detection n circuit enabled
  [4:0] PVDLVL — Detection Voltage n Level Select
{0xA6C+4i} PVD{i}CR0 (i=1..2) 8-bit reset 0x82 — Voltage Monitor {i} Circuit Control Register 0
  [7] RN — Voltage Monitor m Reset Negate Select
  [6] RI — Voltage Monitor m Circuit Mode Select
  [5:4] FSAMP — Sampling Clock Select
    0=1/2 LOCO frequency; 1=1/4 LOCO frequency; 2=1/8 LOCO frequency; 3=1/16 LOCO frequency
  [2] CMPE — Voltage Monitor m Circuit Comparison Result Output Enable
    0=Voltage monitor m circuit comparison result output disabled; 1=Voltage monitor m circuit comparison result output enabled
  [1] DFDIS — Voltage monitor m Digital Filter Disabled Mode Select
    0=Enable the digital filter; 1=Disable the digital filter
  [0] RIE — Voltage Monitor m Interrupt/Reset Enable
    0=Disable; 1=Enable
{0xA6C+4i} PVD{i}CR0 (i=4..5) 8-bit reset 0x42 — Voltage Monitor {i} Circuit Control Register 0
  [5:4] FSAMP — Sampling Clock Select
    values as PVD1CR0.FSAMP
  [2] CMPE — Voltage Monitor n Circuit Comparison Result Output Enable
    0=Voltage monitor n circuit comparison result output disabled; 1=Voltage monitor n circuit comparison result output enabled
  [1] DFDIS — Voltage Monitor n Digital Filter Disable Mode Select
    0=Digital filter enabled; 1=Digital filter disabled
  [0] RE — Voltage Monitor n Reset Enable
    0=Disabled; 1=Enabled
0xA84 VBATTMNSELR 8-bit — Battery Backup Voltage Monitor Function Select Register
  [0] VBTMNSEL — VBATT Voltage Monitor Function Select Bit
    0=Disables VBATT voltage monitor function; 1=Enables VBATT voltage monitor function
0xA88 VBTBPCR1 8-bit — VBATT Battery Power Supply Control Register 1
  [0] BPWSWSTP — Battery Power Supply Switch Stop
    0=Battery power supply switch enable; 1=Battery power supply switch stop
0xA90 LPSCR 8-bit reset 0x4 — Low Power State Control Register
  [3:0] LPMD — Low power mode setting
    0=System Active; 5=Software Standby mode; 8=Deep Software Standby mode 1; 9=Deep Software Standby mode 2; 10=Deep Software Standby mode 3
0xA98 SSCR1 8-bit — Software Standby Control Register 1
  [3:2] SS2LP — Software Standby low power select
    0=SS2LP_0 (default mode); 1=SS2LP_1 (Low power setting 1)
  [0] SS2FR — Software Standby Fast Return
    0=When returning from Software Standby mode, fast return function is disabled; 1=When returning from Software Standby mode, fast return function is enabled
0xA9C SVSCR 8-bit reset 0x2 — SSTBY Voltage Scaling Control Register
  [2:0] SVSCM — SSTBY Voltage Scaling Control Mode Bit
    1=SVSCR_1; 2=SVSCR_2 (default); 3=SVSCR_3; 4=SVSCR_4; 5=SVSCR_5
0xAB0 LVOCR 8-bit reset 0x3 — Low Voltage Operation Control Register
  [1] LVO1E — Low Voltage Operation 1 Enable
    0=Disable; 1=Enable
  [0] LVO0E — Low Voltage Operation 0 Enable
    0=Disable; 1=Enable
0xAB4 MWMCR 8-bit — OTP Write Mode Control Register
  [1:0] MWM — OTP Write Mode [1:0]
    0=OTP normal speed write mode; 1=OTP high speed write mode 0; 2=OTP high speed write mode 1; 3=Prohibited
0xAD0 SYRSTMSK0 8-bit — System Reset Mask Control Register 0
  [all] fields
    0=Reset occurrence is enabled; 1=Reset occurrence is disabled
  [7] BUSMASK — Bus Error Reset Mask
  [6] CMMASK — Common Memory Error Reset Mask
  [5] LM0MASK — Local Memory 0 Error Reset Mask
  [4] CLU0MASK — CPU0 Lockup Reset Mask
  [2] SWMASK — Software Reset Mask
  [1] WDT0MASK — CPU0 Watchdog Timer Reset Mask
  [0] IWDTMASK — Independent Watchdog Timer Reset Mask
0xAD4 SYRSTMSK1 8-bit — System Reset Mask Control Register 1
  [all] fields
    values as the fields of SYRSTMSK0
  [5] LM1MASK — Local Memory 1 Error Reset Mask
  [4] CLU1MASK — CPU1 Lockup Reset Mask
  [1] WDT1MASK — CPU1 Watchdog Timer Reset Mask
0xAD8 SYRSTMSK2 8-bit — System Reset Mask Control Register 2
  [1] PVD2MASK — Voltage Monitor 2 Reset Mask
    values as the fields of SYRSTMSK0
  [0] PVD1MASK — Voltage Monitor 1 Reset Mask
    values as the fields of SYRSTMSK0
0xADC TEMPRCR 8-bit — Temperature Monitor Reset Control Register
  [3] TSNKEEP — Temperature Sensor Latch Control
    0=Temperature sensor latch is opened; 1=Temperature sensor latch is closed
  [2] CMPEN — Comparator Enable
    0=Comparator is disabled; 1=Comparator is enabled
  [1] TSNEN — Temperature Sensor Enable
    0=Temperature sensor is disabled; 1=Temperature sensor is enabled
  [0] TEMPREN — Temperature Reset Enable
    0=Temperature reset is disabled; 1=Temperature reset is enabled
0xAE0 TEMPRLR 8-bit reset 0x1 — Temperature Monitor Reset Lock Register
  [0] LOCK — Temperature Monitor Reset Control Register Lock
    0=Temperature monitor reset control register is unlocked; 1=Temperature monitor reset control register is locked
0xB04 PLL1LDOCR 8-bit — PLL1-LDO Control Register
  [1] SKEEP — STBY Keep
    0=PLL1-LDO is stopped during Software Standby mode; 1=PLL1-LDO state before Software Standby mode is retained during Software Standby mode
  [0] LDOSTP — LDO Stop
    0=PLL1-LDO is enabled; 1=PLL1-LDO is stopped
0xB08 PLL2LDOCR 8-bit — PLL2-LDO Control Register
  [1] SKEEP — STBY Keep
    0=PLL2-LDO is stopped during Software Standby mode; 1=PLL2-LDO state before Software Standby mode is retained during Software Standby mode
  [0] LDOSTP — LDO Stop
    0=PLL2-LDO is enabled; 1=PLL2-LDO is stopped
0xB0C HOCOLDOCR 8-bit — HOCO-LDO Control Register
  [1] SKEEP — STBY Keep
    0=HOCO-LDO is stopped during Software Standby mode; 1=HOCO-LDO state before Software Standby mode is retained during Software Standby mode
  [0] LDOSTP — LDO Stop
    0=HOCO-LDO is enabled; 1=HOCO-LDO is stopped
{0xB1C+4i} PVD{i}FCR (i=1..2) 8-bit — Voltage Monitor {i} Function Control Register
  [0] RHSEL — Rise Hysteresis Select
    0=Hysteresis level for VCC-fall detection is selected; 1=Hysteresis level for VCC-rise detection is selected
{0xB1C+4i} PVD{i}FCR (i=4..5) 8-bit — Voltage Monitor {i} Function Control Register
  fields as PVD1FCR
0xB34 PVDLR 8-bit reset 0x1 — Voltage Monitor Lock Register
  [0] LOCK — LOCK control
    0=The control registers for PVD4 and PVD5 can be written; 1=The control registers for PVD4 and PVD5 can not be written
0xB40 DPSIER4 8-bit — Deep Software Standby Interrupt Enable Register 4
  [all] fields
    values as the fields of DPSIER1
  [n-16] DIRQ{n}E (n=16..23) — IRQ{n}-DS Pin Enable
0xB44 DPSIER5 8-bit — Deep Software Standby Interrupt Enable Register 5
  [all] fields
    values as the fields of DPSIER1
  [n-24] DIRQ{n}E (n=24..31) — IRQ{n}-DS Pin Enable
0xB48 DPSIFR4 8-bit — Deep Software Standby Interrupt Flag Register 4
  [all] fields
    values as the fields of DPSIFR0
  [n-16] DIRQ{n}F (n=16..23) — IRQ{n}-DS Pin Deep Software Standby Cancel Flag
0xB4C DPSIFR5 8-bit — Deep Software Standby Interrupt Flag Register 5
  [all] fields
    values as the fields of DPSIFR0
  [n-24] DIRQ{n}F (n=24..31) — IRQ{n}-DS Pin Deep Software Standby Cancel Flag
0xB50 DPSIEGR4 8-bit — Deep Software Standby Interrupt Edge Register 4
  [all] fields
    values as the fields of DPSIEGR0
  [n-24] DIRQ{n}EG (n=24..31) — IRQ{n}-DS Pin Edge Select
0xC00 SOSCCR 8-bit reset 0x1 — Sub-Clock Oscillator Control Register
  [0] SOSTP — Sub-Clock Oscillator Stop
    0=Operate the sub-clock oscillator; 1=Stop the sub-clock oscillator
0xC01 SOMCR 8-bit — Sub-Clock Oscillator Mode Control Register
  [6] SOSEL — Sub-Clock Oscillator Switching
    0=Resonator; 1=External clock input
  [1:0] SODRV — Sub-Clock Oscillator Drive Capability Switching
    0=Standard (12.5pf); 1=Lowpower mode 1 (9pf); 2=Lowpower mode 2 (7pf); 3=Lowpower mode 3 (4pf)
0xC04 SOSTDCR 8-bit — Sub-clock Oscillation Stop Detection Control Register
  [7] SOSTDE — Sub-clock Oscillation Stop Detection Function Enable
    0=Oscillation stop detection function is disabled; 1=Oscillation stop detection function is enabled
  [0] SOSTDIE — Sub-clock Oscillation Stop Detection Interrupt Enable
    0=The oscillation stop detection interrupt is disabled; 1=The oscillation stop detection interrupt is enabled
0xC05 SOSTDSR 8-bit — Sub-clock Oscillation Stop Detection Status Register
  [0] SOSTDF — Sub-clock Oscillation Stop Detection Flag
    0=The sub-clock oscillation stop has not been detected; 1=The sub-clock oscillation stop has been detected
0xC40 VBTBER 8-bit reset 0x8 — VBATT Backup Enable Register
  [3] VBAE — VBATT backup register access enable bit
    0=Disable to access VBTBKR; 1=Enable to access VBTBKR
0xC45 VBTBPCR2 8-bit reset 0x6 — VBATT Battery Power Supply Control Register 2
  [4] VDETE — Voltage drop detection enable
    0=VCC Voltage drop detection disable; 1=VCC Voltage drop detection enable
  [2:0] VDETLVL — VDETBATT Level Select
    0=2.80 V; 1=2.53 V; 2=2.10 V; 3=1.95 V; 4=1.85 V; 5=1.75 V; 6=setting prohibited; 7=setting prohibited
0xC46 VBTBPSR 8-bit (reset mask 0xCE) — VBATT Battery Power Supply Status Register
  [5] BPWSWM ro — Battery Power Supply Switch Status Monitor
    0=VCC voltage < VDETBATT; 1=VCC voltage > VDETBATT
  [4] VBPORM ro — VBATT_POR Monitor
    0=VBATT_R voltage < VPORBATT; 1=VBATT_R voltage > VPORBATT
  [0] VBPORF — VBATT_POR Flag
    0=VBATT_R voltage drop is not detected; 1=VBATT_R voltage drop is detected
0xC48 VBTADSR 8-bit — VBATT Tamper Detection Status Register
  [2] VBTADF2 — VBATT Tamper Detection flag 2
    0=RTCIC2 input edge is not detected; 1=RTCIC2 input edge is detected
  [1] VBTADF1 — VBATT Tamper Detection flag 1
    0=RTCIC1 input edge is not detected; 1=RTCIC1 input edge is detected
  [0] VBTADF0 — VBATT Tamper Detection flag 0
    0=RTCIC0 input edge is not detected; 1=RTCIC0 input edge is detected
0xC49 VBTADCR1 8-bit — VBATT Tamper Detection Control Register 1
  [6] VBTADCE2 — VBATT Tamper Detection Backup Register Clear Enable 2
    0=Clear Backup Register by VBTADF2 flag is disable; 1=Clear Backup Register by VBTADF2 flag is enable
  [5] VBTADCE1 — VBATT Tamper Detection Backup Register Clear Enable 1
    0=Clear Backup Register by VBTADF1 flag is disable; 1=Clear Backup Register by VBTADF1 flag is enable
  [4] VBTADCE0 — VBATT Tamper Detection Backup Register Clear Enable 0
    0=Clear Backup Register by VBTADF0 flag is disable; 1=Clear Backup Register by VBTADF0 flag is enable
  [2] VBTADIE2 — VBATT Tamper Detection Interrupt Enable 2
    0=Interrupt by VBTADF2 flag is disable; 1=Interrupt by VBTADF2 flag is enable
  [1] VBTADIE1 — VBATT Tamper Detection Interrupt Enable 1
    0=Interrupt by VBTADF1 flag is disable; 1=Interrupt by VBTADF1 flag is enable
  [0] VBTADIE0 — VBATT Tamper Detection Interrupt Enable 0
    0=Interrupt by VBTADF0 flag is disable; 1=Interrupt by VBTADF0 flag is enable
0xC4A VBTADCR2 8-bit — VBATT Tamper Detection Control Register 2
  [2] VBRTCES2 — VBATT RTC Time Capture Event Source Select 2
    0=RTCIC2; 1=VBTADF2
  [1] VBRTCES1 — VBATT RTC Time Capture Event Source Select 1
    0=RTCIC1; 1=VBTADF1
  [0] VBRTCES0 — VBATT RTC Time Capture Event Source Select 0
    0=RTCIC0; 1=VBTADF0
0xC4C VBTICTLR 8-bit — VBATT Input Control Register
  [2] VCH2INEN — VBATT CH2 Input Enable
    0=RTCIC2 input disable; 1=RTCIC2 input enable
  [1] VCH1INEN — VBATT CH1 Input Enable
    0=RTCIC1 input disable; 1=RTCIC1 input enable
  [0] VCH0INEN — VBATT CH0 Input Enable
    0=RTCIC0 input disable; 1=RTCIC0 input enable
0xC4D VBTICTLR2 8-bit reset 0x70 — VBATT Input Control Register 2
  [6] VCH2EG — VBATT CH2 Input Edge Select
    0=RTCIC2 pin input event is detected on falling edge; 1=RTCIC2 pin input event is detected on rising edge
  [5] VCH1EG — VBATT CH1 Input Edge Select
    0=RTCIC1 pin input event is detected on falling edge; 1=RTCIC1 pin input event is detected on rising edge
  [4] VCH0EG — VBATT CH0 Input Edge Select
    0=RTCIC0 pin input event is detected on falling edge; 1=RTCIC0 pin input event is detected on rising edge
  [2] VCH2NCE — VBATT CH2 Input Noise Canceler Enable
    0=RTCIC2 pin input noise canceler disable; 1=RTCIC2 pin input noise canceler enable
  [1] VCH1NCE — VBATT CH1 Input Noise Canceler Enable
    0=RTCIC1 pin input noise canceler disable; 1=RTCIC1 pin input noise canceler enable
  [0] VCH0NCE — VBATT CH0 Input Noise Canceler Enable
    0=RTCIC0 pin input noise canceler disable; 1=RTCIC0 pin input noise canceler enable
0xC4E VBTIMONR 8-bit (reset mask 0xF8) — VBATT Input Monitor Register
  [2] VCH2MON ro — VBATT CH2 Input monitor
    0=RTCIC2 pin input is low level; 1=RTCIC2 pin input is high level
  [1] VCH1MON ro — VBATT CH1 Input monitor
    0=RTCIC1 pin input is low level; 1=RTCIC1 pin input is high level
  [0] VCH0MON ro — VBATT CH0 Input monitor
    0=RTCIC0 pin input is low level; 1=RTCIC0 pin input is high level
0xC50 VBTNCWCR 8-bit — VBATT Noise Canceler Width Control Register
  [2:0] VINCW — VBATT Input Noise Canceler Width select
    0=32.768 kHz; 1=64 Hz; 2=32 Hz; 3=16 Hz; 4=8 Hz; 5=4 Hz; 6=2 Hz; 7=1 Hz
0xC54 VBTADCR3 8-bit — VBATT Tamper Detection Control Register 3
  [2] VBTADZE2 — VBATT Tamper Detection Zeroization Enable 2
    0=Zeroing HUK request by VBTADF2 flag is disable; 1=Zeroing HUK request by VBTADF2 flag is enable
  [1] VBTADZE1 — VBATT Tamper Detection Zeroization Enable 1
    0=Zeroing HUK request by VBTADF1 flag is disable; 1=Zeroing HUK request by VBTADF1 flag is enable
  [0] VBTADZE0 — VBATT Tamper Detection Zeroization Enable 0
    0=Zeroing HUK request by VBTADF0 flag is disable; 1=Zeroing HUK request by VBTADF0 flag is enable
{0xD00+i} VBTBKR{i} (i=0..127) 8-bit — VBATT Backup Register
  [7:0] VBTBKRn

## SYSC_NS — System Control
Base 0x5001E000
Registers as SYSC, without VBRSABAR, VBRPABARS, PRCR_S; these are added or differ:
0x3B8 VBRPABARNS 16-bit — VBATT Backup Register Privilege Attribute Boundary Address Register for Non-secure Region
  [15:0] PABANS — Privilege Attribute Boundary Address for Non-secure Region
0x3FE PRCR_NS 16-bit — Protect Register for Non-Secure
  [15:8] PRKEY wo — PRC Key Code
  [4] PRC4
    0=Write disabled; 1=Write enabled
  [3] PRC3 — Enable writing to the registers related to the PVD
    0=Write disabled; 1=Write enabled
  [1] PRC1 — Enable writing to the registers related to the low power modes, and the battery backup function
    0=Write disabled; 1=Write enabled
  [0] PRC0 — Enable writing to the registers related to the clock generation circuit
    0=Write disabled; 1=Write enabled

## Notices in the file
This software is supplied by Renesas Electronics Corporation and is only intended for
use with Renesas products. No other uses are authorized. This software is owned by
Renesas Electronics Corporation and is protected under all applicable laws, including
copyright laws.
THIS SOFTWARE IS PROVIDED "AS IS" AND RENESAS MAKES NO WARRANTIES REGARDING
THIS SOFTWARE, WHETHER EXPRESS, IMPLIED OR STATUTORY, INCLUDING BUT NOT LIMITED TO
WARRANTIES OF MERCHANTABILITY, FITNESS FOR A PARTICULAR PURPOSE AND NON-INFRINGEMENT.
ALL SUCH WARRANTIES ARE EXPRESSLY DISCLAIMED. TO THE MAXIMUM EXTENT PERMITTED NOT
PROHIBITED BY LAW, NEITHER RENESAS ELECTRONICS CORPORATION NOR ANY OF ITS AFFILIATED
COMPANIES SHALL BE LIABLE FOR ANY DIRECT, INDIRECT, SPECIAL, INCIDENTAL OR CONSEQUENTIAL
DAMAGES FOR ANY REASON RELATED TO THIS SOFTWARE, EVEN IF RENESAS OR ITS AFFILIATES HAVE
BEEN ADVISED OF THE POSSIBILITY OF SUCH DAMAGES.
Renesas reserves the right, without notice, to make changes to this software and to
discontinue the availability of this software. By using this software, you agree to
the additional terms and conditions found by accessing the following link:
http://www.renesas.com/disclaimer
